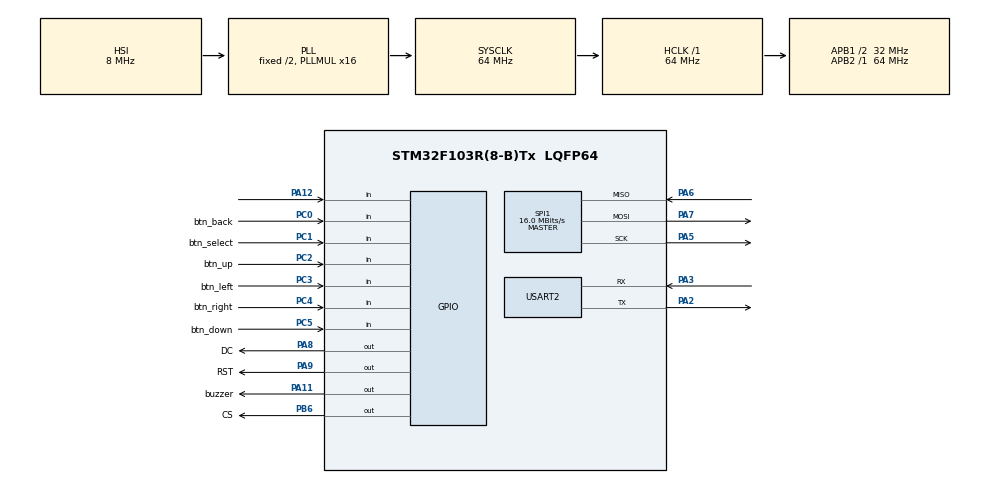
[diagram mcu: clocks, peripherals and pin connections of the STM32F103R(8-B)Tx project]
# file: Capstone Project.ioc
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Mcu.Family=STM32F1
Mcu.Name=STM32F103R(8-B)Tx
Mcu.Package=LQFP64
NVIC.PriorityGroup=NVIC_PRIORITYGROUP_4
PA11.GPIO_Label=buzzer
PA11.Signal=GPIO_Output
PA12.Signal=GPIO_Input
PA13.Mode=Serial_Wire
PA13.Signal=SYS_JTMS-SWDIO
PA14.Mode=Serial_Wire
PA14.Signal=SYS_JTCK-SWCLK
PA2.Mode=Asynchronous
PA2.Signal=USART2_TX
PA3.Mode=Asynchronous
PA3.Signal=USART2_RX
PA5.Mode=Full_Duplex_Master
PA5.Signal=SPI1_SCK
PA6.Mode=Full_Duplex_Master
PA6.Signal=SPI1_MISO
PA7.Mode=Full_Duplex_Master
PA7.Signal=SPI1_MOSI
PA8.GPIO_Label=DC
PA8.PinState=GPIO_PIN_SET
PA8.Signal=GPIO_Output
PA9.GPIO_Label=RST
PA9.PinState=GPIO_PIN_SET
PA9.Signal=GPIO_Output
PB6.GPIO_Label=CS
PB6.PinState=GPIO_PIN_SET
PB6.Signal=GPIO_Output
PC0.GPIO_Label=btn_back
PC0.Signal=GPIO_Input
PC1.GPIO_Label=btn_select
PC1.Signal=GPIO_Input
PC2.GPIO_Label=btn_up
PC2.Signal=GPIO_Input
PC3.GPIO_Label=btn_left
PC3.Signal=GPIO_Input
PC4.GPIO_Label=btn_right
PC4.Signal=GPIO_Input
PC5.GPIO_Label=btn_down
PC5.Signal=GPIO_Input
PD0-OSC_IN.Mode=HSE-External-Clock-Source
PD0-OSC_IN.Signal=RCC_OSC_IN
PD1-OSC_OUT.Mode=HSE-External-Clock-Source
PD1-OSC_OUT.Signal=RCC_OSC_OUT
ProjectManager.HeapSize=0x200
ProjectManager.StackSize=0x400
ProjectManager.TargetToolchain=STM32CubeIDE
RCC.AHBFreq_Value=64000000
RCC.APB1CLKDivider=RCC_HCLK_DIV2
RCC.APB1Freq_Value=32000000
RCC.APB1TimFreq_Value=64000000
RCC.APB2Freq_Value=64000000
RCC.APB2TimFreq_Value=64000000
RCC.HCLKFreq_Value=64000000
RCC.PLLMUL=RCC_PLL_MUL16
RCC.RTCClockSelection=RCC_RTCCLKSOURCE_LSE
RCC.SYSCLKFreq_VALUE=64000000
RCC.SYSCLKSource=RCC_SYSCLKSOURCE_PLLCLK
RCC.USBFreq_Value=64000000
SPI1.BaudRatePrescaler=SPI_BAUDRATEPRESCALER_4
SPI1.CalculateBaudRate=16.0 MBits/s
SPI1.Direction=SPI_DIRECTION_2LINES
SPI1.Mode=SPI_MODE_MASTER
SPI1.VirtualType=VM_MASTER
USART2.VirtualMode=VM_ASYNC
board=NUCLEO-F103RB

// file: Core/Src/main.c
/* USER CODE BEGIN Header */
/**
 ******************************************************************************
 * @file           : main.c
 * @brief          : Main program body
 ******************************************************************************
 * @attention
 *
 * Copyright (c) 2025 STMicroelectronics.
 * All rights reserved.
 *
 * This software is licensed under terms that can be found in the LICENSE file
 * in the root directory of this software component.
 * If no LICENSE file comes with this software, it is provided AS-IS.
 *
 ******************************************************************************
 */
/* USER CODE END Header */
#include "main.h"

/* USER CODE BEGIN Includes */
#include <string.h>
#include <time.h>
#include <stdlib.h>

#include "menu_main.h"
#include "lcd_driver.h"
#include "input.h"

/* USER CODE END Includes */

/* USER CODE BEGIN PD */

#define MENU_ITEMS     2

#define LCD_CS_Pin GPIO_PIN_6

#define LCD_CS_GPIO_Port GPIOB

#define LCD_DC_Pin GPIO_PIN_8

#define LCD_DC_GPIO_Port GPIOA

#define LCD_RST_Pin GPIO_PIN_9

#define LCD_RST_GPIO_Port GPIOA
/* USER CODE END PD */

SPI_HandleTypeDef hspi1;

UART_HandleTypeDef huart2;

void SystemClock_Config(void);
static void MX_GPIO_Init(void);
static void MX_SPI1_Init(void);
static void MX_USART2_UART_Init(void);

/* USER CODE BEGIN 0 */
void SystemClock_Config(void);

static void MX_GPIO_Init(void);

static void MX_SPI1_Init(void);

/* USER CODE END 0 */

int main(void)
{

  /* MCU Configuration--------------------------------------------------------*/

  /* Reset of all peripherals, Initializes the Flash interface and the Systick. */
  HAL_Init();

  /* Configure the system clock */
  SystemClock_Config();

  /* Initialize all configured peripherals */
  MX_GPIO_Init();
  MX_SPI1_Init();
  MX_USART2_UART_Init();
  /* USER CODE BEGIN 2 */
  // Initialize random seed only once
  srand(time(NULL));
  displayStartup();
//  play_pacman();
//  play_pong();

	// BUZZER TEST PROGRAM
//	while (1) {
//	    toggle_PA11();  // Toggle PA                                                                                                                                                                                                                                                                                                                                                                                                                                                                                                                                                                                                                                                                                                       11
//	    HAL_Delay(5); // 5ms delay
//	}
  /* USER CODE END 2 */

  /* Infinite loop */
	while (1) {
		displayMenu();
	}
}

void SystemClock_Config(void)
{
  RCC_OscInitTypeDef RCC_OscInitStruct = {0};
  RCC_ClkInitTypeDef RCC_ClkInitStruct = {0};

  /** Initializes the RCC Oscillators according to the specified parameters
  * in the RCC_OscInitTypeDef structure.
  */
  RCC_OscInitStruct.OscillatorType = RCC_OSCILLATORTYPE_HSI;
  RCC_OscInitStruct.HSIState = RCC_HSI_ON;
  RCC_OscInitStruct.HSICalibrationValue = RCC_HSICALIBRATION_DEFAULT;
  RCC_OscInitStruct.PLL.PLLState = RCC_PLL_ON;
  RCC_OscInitStruct.PLL.PLLSource = RCC_PLLSOURCE_HSI_DIV2;
  RCC_OscInitStruct.PLL.PLLMUL = RCC_PLL_MUL16;
  if (HAL_RCC_OscConfig(&RCC_OscInitStruct) != HAL_OK)
  {
    Error_Handler();
  }

  /** Initializes the CPU, AHB and APB buses clocks
  */
  RCC_ClkInitStruct.ClockType = RCC_CLOCKTYPE_HCLK|RCC_CLOCKTYPE_SYSCLK
                              |RCC_CLOCKTYPE_PCLK1|RCC_CLOCKTYPE_PCLK2;
  RCC_ClkInitStruct.SYSCLKSource = RCC_SYSCLKSOURCE_PLLCLK;
  RCC_ClkInitStruct.AHBCLKDivider = RCC_SYSCLK_DIV1;
  RCC_ClkInitStruct.APB1CLKDivider = RCC_HCLK_DIV2;
  RCC_ClkInitStruct.APB2CLKDivider = RCC_HCLK_DIV1;

  if (HAL_RCC_ClockConfig(&RCC_ClkInitStruct, FLASH_LATENCY_2) != HAL_OK)
  {
    Error_Handler();
  }
}

static void MX_SPI1_Init(void)
{

  /* SPI1 parameter configuration*/
  hspi1.Instance = SPI1;
  hspi1.Init.Mode = SPI_MODE_MASTER;
  hspi1.Init.Direction = SPI_DIRECTION_2LINES;
  hspi1.Init.DataSize = SPI_DATASIZE_8BIT;
  hspi1.Init.CLKPolarity = SPI_POLARITY_LOW;
  hspi1.Init.CLKPhase = SPI_PHASE_1EDGE;
  hspi1.Init.NSS = SPI_NSS_SOFT;
  hspi1.Init.BaudRatePrescaler = SPI_BAUDRATEPRESCALER_4;
  hspi1.Init.FirstBit = SPI_FIRSTBIT_MSB;
  hspi1.Init.TIMode = SPI_TIMODE_DISABLE;
  hspi1.Init.CRCCalculation = SPI_CRCCALCULATION_DISABLE;
  hspi1.Init.CRCPolynomial = 10;
  if (HAL_SPI_Init(&hspi1) != HAL_OK)
  {
    Error_Handler();
  }

}

static void MX_USART2_UART_Init(void)
{

  huart2.Instance = USART2;
  huart2.Init.BaudRate = 115200;
  huart2.Init.WordLength = UART_WORDLENGTH_8B;
  huart2.Init.StopBits = UART_STOPBITS_1;
  huart2.Init.Parity = UART_PARITY_NONE;
  huart2.Init.Mode = UART_MODE_TX_RX;
  huart2.Init.HwFlowCtl = UART_HWCONTROL_NONE;
  huart2.Init.OverSampling = UART_OVERSAMPLING_16;
  if (HAL_UART_Init(&huart2) != HAL_OK)
  {
    Error_Handler();
  }

}

static void MX_GPIO_Init(void)
{
  GPIO_InitTypeDef GPIO_InitStruct = {0};

  /* GPIO Ports Clock Enable */
  __HAL_RCC_GPIOD_CLK_ENABLE();
  __HAL_RCC_GPIOC_CLK_ENABLE();
  __HAL_RCC_GPIOA_CLK_ENABLE();
  __HAL_RCC_GPIOB_CLK_ENABLE();

  /*Configure GPIO pin Output Level */
  HAL_GPIO_WritePin(BL_GPIO_Port, BL_Pin, GPIO_PIN_SET);

  /*Configure GPIO pin Output Level */
  HAL_GPIO_WritePin(GPIOA, DC_Pin|RST_Pin, GPIO_PIN_SET);

  /*Configure GPIO pin Output Level */
  HAL_GPIO_WritePin(buzzer_GPIO_Port, buzzer_Pin, GPIO_PIN_RESET);

  /*Configure GPIO pin Output Level */
  HAL_GPIO_WritePin(CS_GPIO_Port, CS_Pin, GPIO_PIN_SET);

  /*Configure GPIO pins : btn_back_Pin btn_select_Pin btn_up_Pin btn_left_Pin
                           btn_right_Pin btn_down_Pin */
  GPIO_InitStruct.Pin = btn_back_Pin|btn_select_Pin|btn_up_Pin|btn_left_Pin
                          |btn_right_Pin|btn_down_Pin;
  GPIO_InitStruct.Mode = GPIO_MODE_INPUT;
  GPIO_InitStruct.Pull = GPIO_NOPULL;
  HAL_GPIO_Init(GPIOC, &GPIO_InitStruct);

  /*Configure GPIO pin : BL_Pin */
  GPIO_InitStruct.Pin = BL_Pin;
  GPIO_InitStruct.Mode = GPIO_MODE_OUTPUT_PP;
  GPIO_InitStruct.Pull = GPIO_NOPULL;
  GPIO_InitStruct.Speed = GPIO_SPEED_FREQ_LOW;
  HAL_GPIO_Init(BL_GPIO_Port, &GPIO_InitStruct);

  /*Configure GPIO pins : DC_Pin RST_Pin buzzer_Pin */
  GPIO_InitStruct.Pin = DC_Pin|RST_Pin|buzzer_Pin;
  GPIO_InitStruct.Mode = GPIO_MODE_OUTPUT_PP;
  GPIO_InitStruct.Pull = GPIO_NOPULL;
  GPIO_InitStruct.Speed = GPIO_SPEED_FREQ_LOW;
  HAL_GPIO_Init(GPIOA, &GPIO_InitStruct);

  /*Configure GPIO pin : PA12 */
  GPIO_InitStruct.Pin = GPIO_PIN_12;
  GPIO_InitStruct.Mode = GPIO_MODE_INPUT;
  GPIO_InitStruct.Pull = GPIO_NOPULL;
  HAL_GPIO_Init(GPIOA, &GPIO_InitStruct);

  /*Configure GPIO pin : CS_Pin */
  GPIO_InitStruct.Pin = CS_Pin;
  GPIO_InitStruct.Mode = GPIO_MODE_OUTPUT_PP;
  GPIO_InitStruct.Pull = GPIO_NOPULL;
  GPIO_InitStruct.Speed = GPIO_SPEED_FREQ_LOW;
  HAL_GPIO_Init(CS_GPIO_Port, &GPIO_InitStruct);

}

/* USER CODE BEGIN 4 */
void print(char *str) {
    // Calculate the length of the string
    uint16_t len = strlen(str);

    // Transmit the string over UART2
    HAL_UART_Transmit(&huart2, (uint8_t*)str, len, HAL_MAX_DELAY);
}
/* USER CODE END 4 */

void Error_Handler(void)
{
	__disable_irq();
	while (1) {
	}
}
